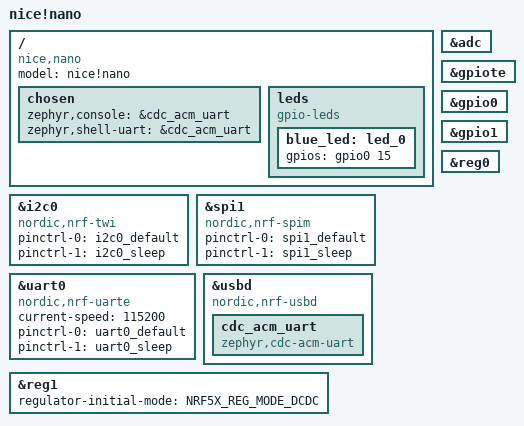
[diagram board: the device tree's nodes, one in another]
/*
 * Copyright (c) 2021 The ZMK Contributors
 *
 * SPDX-License-Identifier: MIT
 */

/dts-v1/;
#include <nordic/nrf52840_qiaa.dtsi>
#include <nordic/nrf52840_partition.dtsi>
#include "nice_nano-pinctrl.dtsi"

/ {
	model = "nice!nano";
	compatible = "nice,nano";

	chosen {
		zephyr,console = &cdc_acm_uart;
		zephyr,shell-uart = &cdc_acm_uart;
	};

	leds {
		compatible = "gpio-leds";
		blue_led: led_0 {
			gpios = <&gpio0 15 GPIO_ACTIVE_HIGH>;
		};
	};
};

&adc {
	status = "okay";
};

&gpiote {
	status = "okay";
};

&gpio0 {
	status = "okay";
};

&gpio1 {
	status = "okay";
};

&i2c0 {
	status = "okay";

	compatible = "nordic,nrf-twi";
	pinctrl-0 = <&i2c0_default>;
	pinctrl-1 = <&i2c0_sleep>;
	pinctrl-names = "default", "sleep";
};

&spi1 {
	compatible = "nordic,nrf-spim";
	pinctrl-0 = <&spi1_default>;
	pinctrl-1 = <&spi1_sleep>;
	pinctrl-names = "default", "sleep";
};

&uart0 {
	compatible = "nordic,nrf-uarte";
	current-speed = <115200>;
	pinctrl-0 = <&uart0_default>;
	pinctrl-1 = <&uart0_sleep>;
	pinctrl-names = "default", "sleep";
};

zephyr_udc0: &usbd {
	compatible = "nordic,nrf-usbd";
	status = "okay";

	cdc_acm_uart: cdc_acm_uart {
		compatible = "zephyr,cdc-acm-uart";
	};
};

&reg0 {
	status = "okay";
};

&reg1 {
	regulator-initial-mode = <NRF5X_REG_MODE_DCDC>;
};
